# BL616/BL618 register map
Vendor: Bouffalo Lab; File version: 1.0
Registers are 32-bit, read-write, reset 0x0 unless marked. A register's access mark holds for its fields unless they carry their own. Offsets are from the block's base; [hi:lo] are bit positions; {n}, {i} and the like mark numbered series; 'fields as' and 'values as' point back to an identical list.

## IR — Infrared receiver module
Base 0x2000A600
0x00 transmit_config — ??
0x04 transmit_interrupt — ??
{0x8+4i} transmit_data[{i}] (i=0..1) — ??
0x10 transmit_width — ??
0x80 receive_config — ??
0x84 receive_interrupt — ??
0x88 receive_width — ??
0x90 receive_bit_count — ??
{0x94+4i} receive_data[{i}] (i=0..1) — ??

## CRC — Checksum peripheral
Base 0x2000A700
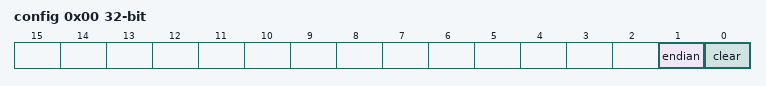
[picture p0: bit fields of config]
0x00 config — Configuration register
  [1] endian — Sets endian of input data
    0=Little endian; 1=big (Big endian)
  [0] clear wo — Write 1 to clear internal checksum states
    1=clear (Write 1 to clear internal states)
0x04 input wo — Data input register
  [31:0] data — Write data value into checksum calculator
0x08 output ro — Checksum output register
  [15:0] checksum — Read checksum from peripheral

## I2S — Inter-IC Sound controller
Base 0x2000AB00
0x00 config — Function configuration register
0x04 interrupt_state — Interrupt enables, masks and states
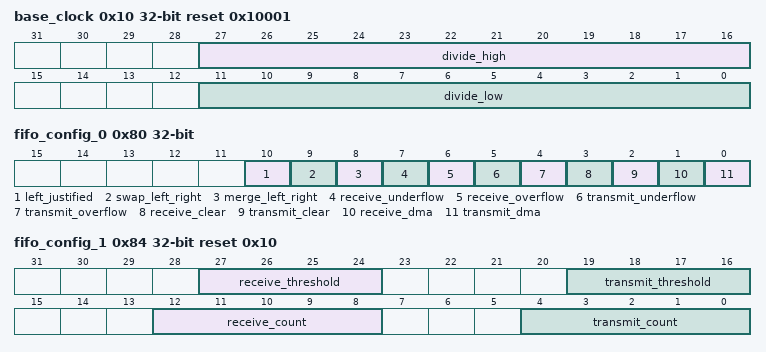
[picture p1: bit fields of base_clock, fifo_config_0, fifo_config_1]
0x10 base_clock reset 0x10001 — Base clock divider
  [27:16] divide_high — Higher half of base clock dividing factor
  [11:0] divide_low — Lower half of base clock dividing factor
0x80 fifo_config_0 — FIFO configuration register 0
  [10] left_justified
  [9] swap_left_right
  [8] merge_left_right
  [7] receive_underflow ro — Receive FIFO underflow flag . Can be cleared using `receive_clear`.
    0=not_underflow (No FIFO buffer underflow); 1=underflow (Has FIFO buffer underflow)
  [6] receive_overflow ro — Receive FIFO overflow flag . Can be cleared using `receive_clear`.
    0=not_overflow (No FIFO buffer overflow); 1=overflow (Has FIFO buffer overflow)
  [5] transmit_underflow ro — Transmit FIFO underflow flag . Can be cleared using `transmit_clear`.
    values as receive_underflow
  [4] transmit_overflow ro — Transmit FIFO overflow flag . Can be cleared using `transmit_clear`.
    values as receive_overflow
  [3] receive_clear wo — Clears receive FIFO overflow and underflow flags
    1=clear (Write 1 to clear fifo flags)
  [2] transmit_clear wo — Clears transmit FIFO overflow and underflow flags
    1=clear (Write 1 to clear fifo flags)
  [1] receive_dma — Enable signal of receive DMA interface
    1=Enable DMA interface; 0=Disable DMA interface
  [0] transmit_dma — Enable signal of transmit DMA interface
    1=Enable DMA interface; 0=Disable DMA interface
0x84 fifo_config_1 reset 0x10 — FIFO configuration register 1
  [27:24] receive_threshold — Receive FIFO threshold . DMA request will not be asserted if `receive_available` is less than this value
  [19:16] transmit_threshold — Transmit FIFO threshold . DMA request will not be asserted if `transmit_available` is less than this value
  [12:8] receive_count ro — Count of available data in receive FIFO
  [4:0] transmit_count ro — Count of available data in transmit FIFO
0x88 data_write wo — FIFO write data register
  [7:0] value — Write data to FIFO
0x8C data_read ro — FIFO read data register
  [7:0] value — Read data from FIFO

## AUADC — Analog-to-Digital or Pulse-Density audio input
Base 0x2000AC00
0x00 clock — Peripheral clock control register
0x04 interface_0 — Interface control register 0
0x08 finite_impulse — Finite Impulse Response control
0x0C high_pass — High-Pass Filter control register
0x10 interface_1 — Interface control register 1
0x1C pulse_width — Pulse-Width Modulator control
0x38 volume — Volume control register
0x60 analog_0 — Analog signal configuration 0
0x64 analog_1 — Analog signal configuration 1
0x68 command — Analog-to-Digital Converter commands
0x6C sample_data — Analog-to-Digital Converter sample output
0x80 fifo_control — Controls audio input FIFO
0x84 fifo_state — Gets states of audio input FIFO
0x88 fifo_data — Reads data from audio input FIFO
